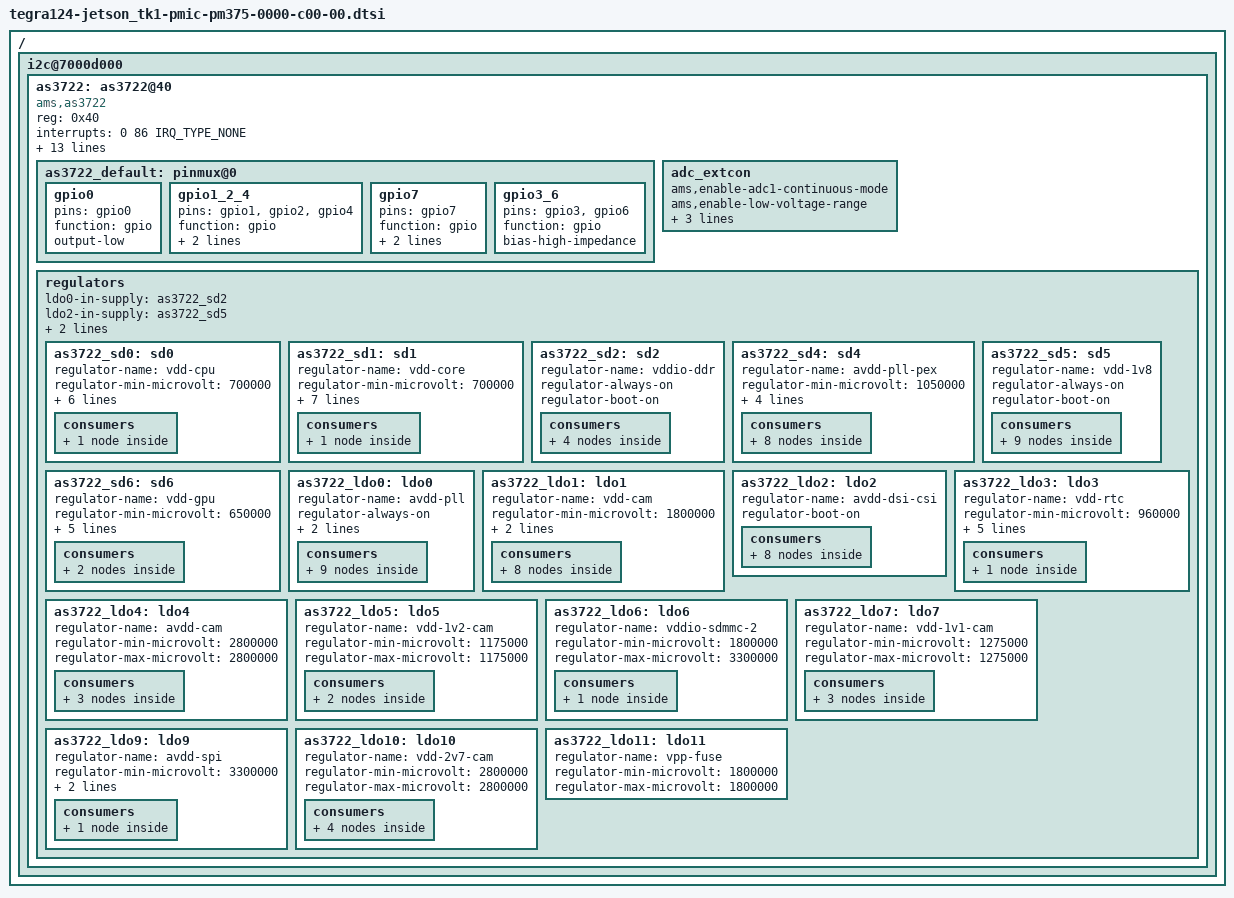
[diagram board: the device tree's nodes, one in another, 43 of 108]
 #include <dt-bindings/gpio/tegra-gpio.h>
 #include <dt-bindings/mfd/as3722.h>
 #include <dt-bindings/regulator/regulator.h>

/ {
	i2c@7000d000 {
		as3722: as3722@40 {
			compatible = "ams,as3722";
			reg = <0x40>;
			interrupts = <0 86 IRQ_TYPE_NONE>;

			#interrupt-cells = <2>;
			interrupt-controller;

			gpio-controller;
			#gpio-cells = <2>;

			ams,major-rev = <1>;
			ams,minor-rev = <2>;
			ams,system-power-controller;
			ams,enable-clock32k-out;
			ams,backup-battery-chargable;
			ams,battery-backup-charge-current = <AS3722_BBCCUR_400UA>;
			ams,battery-backup-bypass-out-resistor;
			ams,battery-backup-charge-mode = <AS3722_BBCMODE_ACT_STBY_OFF>;

			pinctrl-names = "default";
			pinctrl-0 = <&as3722_default>;

			as3722_default: pinmux@0 {
				gpio0 {
					pins = "gpio0";
					function = "gpio";
					output-low;
				};

				gpio1_2_4 {
					pins = "gpio1", "gpio2", "gpio4";
					function = "gpio";
					bias-pull-down;
					output-high;
				};

				gpio7 {
					pins = "gpio7";
					function = "gpio";
					bias-pull-up;
					output-high;
				};

				gpio3_6 {
					pins = "gpio3", "gpio6";
					function = "gpio";
					bias-high-impedance;
				};
			};

			adc_extcon: adc_extcon {
				ams,enable-adc1-continuous-mode;
				ams,enable-low-voltage-range;
				ams,adc-channel = <12>;
				ams,hi-threshold = <256>;
				ams,low-threshold = <128>;
				#extcon-cells = <1>;
				#io-channel-cells = <1>;
			};

		     	regulators {
			     ldo0-in-supply = <&as3722_sd2>;
			     ldo2-in-supply = <&as3722_sd5>;
			     ldo5-in-supply = <&as3722_sd5>;
			     ldo7-in-supply = <&as3722_sd5>;

				as3722_sd0: sd0 {
				    regulator-name = "vdd-cpu";
				    regulator-min-microvolt = <700000>;
				    regulator-max-microvolt = <1400000>;
				    regulator-min-microamp = <3500000>;
				    regulator-max-microamp = <3500000>;
				    regulator-always-on;
				    regulator-boot-on;
				    ams,ext-control = <AS3722_EXT_CONTROL_ENABLE2>;
				    consumers {
					    c1 {
					    regulator-consumer-supply = "vdd_cpu";
					    };
				    };
			    };

				as3722_sd1: sd1 {
				    regulator-name = "vdd-core";
				    regulator-min-microvolt = <700000>;
				    regulator-max-microvolt = <1350000>;
				    regulator-min-microamp = <3500000>;
				    regulator-max-microamp = <3500000>;
				    regulator-init-microvolt = <1000000>;
				    regulator-always-on;
				    regulator-boot-on;
				    ams,ext-control = <AS3722_EXT_CONTROL_ENABLE1>;
				    consumers {
					    c1 {
						    regulator-consumer-supply = "vdd_core";
					    };
				    };
			    };

				as3722_sd2:  sd2 {
				     regulator-name = "vddio-ddr";
				     regulator-always-on;
				     regulator-boot-on;

				     consumers {
					     c1 {
						     regulator-consumer-supply = "vddio_ddr";
					     };
					     c2 {
						     regulator-consumer-supply = "vddio_ddr_mclk";
					     };
					     c3 {
						     regulator-consumer-supply = "vddio_ddr3";
					     };
					     c4 {
						     regulator-consumer-supply = "vcore1_ddr3";
					     };
				     };

			     };

				as3722_sd4: sd4 {
				    regulator-name = "avdd-pll-pex";
				    regulator-min-microvolt = <1050000>;
				    regulator-max-microvolt = <1050000>;
				    regulator-always-on;
				    regulator-boot-on;
				    ams,ext-control = <AS3722_EXT_CONTROL_ENABLE1>;

				    consumers {
					    c1 {
						    regulator-consumer-supply = "avdd_pex_pll";
					    };
					    c2 {
						    regulator-consumer-supply = "avddio_pex_pll";
					    };
					    c3 {
						    regulator-consumer-supply = "dvddio_pex";
					    };
					    c5 {
						    regulator-consumer-supply = "avdd_sata";
					    };
					    c6 {
						    regulator-consumer-supply = "vdd_sata";
					    };
					    c7 {
						    regulator-consumer-supply = "avdd_sata_pll";
					    };
					    c9 {
						    regulator-consumer-supply = "avdd_hdmi";
						    regulator-consumer-device = "tegradc.1";
					    };
					    c10 {
						    regulator-consumer-supply = "avdd_hdmi";
						    regulator-consumer-device = "tegradc.0";
					    };
				    };
			    };

				as3722_sd5: sd5 {
				    regulator-name = "vdd-1v8";
				    regulator-always-on;
				    regulator-boot-on;

				    consumers {
					    c1 {
						    regulator-consumer-supply = "vddio_sys";
					    };
					    c2 {
						    regulator-consumer-supply = "vddio_sys_2";
					    };
					    c3 {
						    regulator-consumer-supply = "vddio_audio";
					    };
					    c5 {
						    regulator-consumer-supply = "vddio_sdmmc";
						    regulator-consumer-device = "sdhci-tegra.0";
					    };
					    c7 {
						    regulator-consumer-supply = "vddio_sdmmc";
						    regulator-consumer-device = "sdhci-tegra.3";
					    };
					    c9 {
						    regulator-consumer-supply = "vddio_uart";
					    };
					    c11 {
						    regulator-consumer-supply = "vddio_bb";
					    };
					    c13 {
						    regulator-consumer-supply = "vddio_gmi";
					    };
					    c15 {
						    regulator-consumer-supply = "avdd_osc";
					    };
				    };
			    };

				as3722_sd6: sd6 {
				    regulator-name = "vdd-gpu";
				    regulator-min-microvolt = <650000>;
				    regulator-max-microvolt = <1200000>;
				    regulator-min-microamp = <3500000>;
				    regulator-max-microamp = <3500000>;
				    regulator-init-microvolt = <1000000>;
				    regulator-boot-on;

				    consumers {
					    c1 {
					    regulator-consumer-supply = "vdd_gpu";
					    };
					    c2 {
					    regulator-consumer-supply = "vdd_gpu_simon";
					    };
				    };
			    };

				as3722_ldo0: ldo0 {
				     regulator-name = "avdd-pll";
				     regulator-always-on;
				     regulator-boot-on;
				     ams,ext-control = <AS3722_EXT_CONTROL_ENABLE1>;

				     consumers {
					     c1 {
						     regulator-consumer-supply = "avdd_pll_m";
					     };
					     c2 {
						     regulator-consumer-supply = "avdd_pll_ap_c2_c3";
					     };
					     c3 {
						     regulator-consumer-supply = "avdd_pll_cud2dpd";
					     };
					     c4 {
						     regulator-consumer-supply = "avdd_pll_c4";
					     };
					     c5 {
						     regulator-consumer-supply = "avdd_lvds0_io";
					     };
					     c6 {
						     regulator-consumer-supply = "vddio_ddr_hs";
					     };
					     c7 {
						     regulator-consumer-supply = "avdd_pll_erefe";
					     };
					     c8 {
						     regulator-consumer-supply = "avdd_pll_x";
					     };
					     c9 {
						     regulator-consumer-supply = "avdd_pll_cg";
					     };
				     };
			     };

				as3722_ldo1: ldo1 {
				     regulator-name = "vdd-cam";
				     regulator-min-microvolt = <1800000>;
				     regulator-max-microvolt = <1800000>;
				     regulator-boot-on;

				     consumers {
					     c1 {
						     regulator-consumer-supply = "vddio_cam";
						     regulator-consumer-device = "vi";
					     };
					     c3 {
						     regulator-consumer-supply = "vdd_cam_1v8_cam";
					     };
					     c4 {
						     regulator-consumer-supply = "vif";
						     regulator-consumer-device = "2-0010";
					     };
					     c5 {
						     regulator-consumer-supply = "vif";
						     regulator-consumer-device = "2-0036";
					     };
					     c6 {
						     regulator-consumer-supply = "vdd_i2c";
						     regulator-consumer-device = "2-000c";
					     };
					     c7 {
						     regulator-consumer-supply = "vdd_i2c";
						     regulator-consumer-device = "2-0010";
					     };
					     c8 {
						     regulator-consumer-supply = "vif";
						     regulator-consumer-device = "2-0018";
					     };
					     c9 {
						     regulator-consumer-supply = "vi2c";
						     regulator-consumer-device = "2-0030";
					     };
				     };
			     };

				as3722_ldo2: ldo2 {
				     regulator-name = "avdd-dsi-csi";
				     regulator-boot-on;

				     consumers {
					     c1 {
						     regulator-consumer-supply = "vddio_hsic";
						     regulator-consumer-device = "tegra-ehci.1";
					     };
					     c2 {
						     regulator-consumer-supply = "vddio_hsic";
						     regulator-consumer-device = "tegra-ehci.2";
					     };
					     c4 {
						     regulator-consumer-supply = "avdd_dsi_csi";
						     regulator-consumer-device = "tegradc.0";
					     };
					     c5 {
						     regulator-consumer-supply = "avdd_dsi_csi";
						     regulator-consumer-device = "tegradc.1";
					     };
					     c6 {
						     regulator-consumer-supply = "avdd_dsi_csi";
						     regulator-consumer-device = "vi.0";
					     };
					     c7 {
						     regulator-consumer-supply = "avdd_dsi_csi";
						     regulator-consumer-device = "vi.1";
					     };
					     c9 {
						     regulator-consumer-supply = "avdd_hsic_com";
					     };
					     c10 {
						     regulator-consumer-supply = "avdd_hsic_mdm";
					     };
				     };
			     };

				as3722_ldo3: ldo3 {
				     regulator-name = "vdd-rtc";
				     regulator-min-microvolt = <960000>;
				     regulator-max-microvolt = <960000>;
				     regulator-always-on;
				     regulator-boot-on;
				     ams,enable-tracking;
				     ams,disable-tracking-suspend;

				     consumers {
					     c1 {
						     regulator-consumer-supply = "vdd_rtc";
					     };
				     };
			     };

				as3722_ldo4: ldo4 {
				     regulator-name = "avdd-cam";
				     regulator-min-microvolt = <2800000>;
				     regulator-max-microvolt = <2800000>;

				     consumers {
					     c1 {
						     regulator-consumer-supply = "vdd_2v7_hv";
					     };
					     c2 {
						     regulator-consumer-supply = "avdd_cam2_cam";
					     };
					     c3 {
						     regulator-consumer-supply = "vana";
					     };
				     };
			     };

				as3722_ldo5: ldo5 {
				     regulator-name = "vdd-1v2-cam";
				     regulator-min-microvolt = <1175000>;
				     regulator-max-microvolt = <1175000>;

				     consumers {
					     c1 {
						     regulator-consumer-supply = "vdd_1v2_cam";
					     };
					     c2 {
						     regulator-consumer-supply = "vdig";
					     };
				     };
			     };

				as3722_ldo6: ldo6 {
				     regulator-name = "vddio-sdmmc-2";
				     regulator-min-microvolt = <1800000>;
				     regulator-max-microvolt = <3300000>;

				     consumers {
					     c1 {
						     regulator-consumer-supply = "vddio_sdmmc";
						     regulator-consumer-device = "sdhci-tegra.2";
					     };
				     };
			     };

				as3722_ldo7: ldo7 {
				     regulator-name = "vdd-1v1-cam";
				     regulator-min-microvolt = <1275000>;
				     regulator-max-microvolt = <1275000>;

				     consumers {
					     c1 {
						     regulator-consumer-supply = "vdd_cam_1v1_cam";
					     };
					     c2 {
						     regulator-consumer-supply = "imx135_reg2";
					     };
					     c3 {
						     regulator-consumer-supply = "vdig_lv";
						     regulator-consumer-device = "2-0010";
					     };
				     };
			     };

				as3722_ldo9: ldo9 {
				     regulator-name = "avdd-spi";
				     regulator-min-microvolt = <3300000>;
				     regulator-max-microvolt = <3300000>;
				     regulator-boot-on;

				     consumers {
					     c1 {
						     regulator-consumer-supply = "avdd";
						     regulator-consumer-device = "spi0.0";
					     };
				     };
			     };

				as3722_ldo10: ldo10 {
				      regulator-name = "vdd-2v7-cam";
				      regulator-min-microvolt = <2800000>;
				      regulator-max-microvolt = <2800000>;

				      consumers {
					      c1 {
						      regulator-consumer-supply = "avdd_af1_cam";
					      };
					      c2 {
						      regulator-consumer-supply = "avdd_cam1_cam";
					      };
					      c3 {
						      regulator-consumer-supply = "imx135_reg1";
					      };
					      c4 {
						      regulator-consumer-supply = "vdd";
						      regulator-consumer-device = "2-000c";
					      };
				      };
			      };

				as3722_ldo11: ldo11 {
				      regulator-name = "vpp-fuse";
				      regulator-min-microvolt = <1800000>;
				      regulator-max-microvolt = <1800000>;
				};
			};
		};
	};
};
